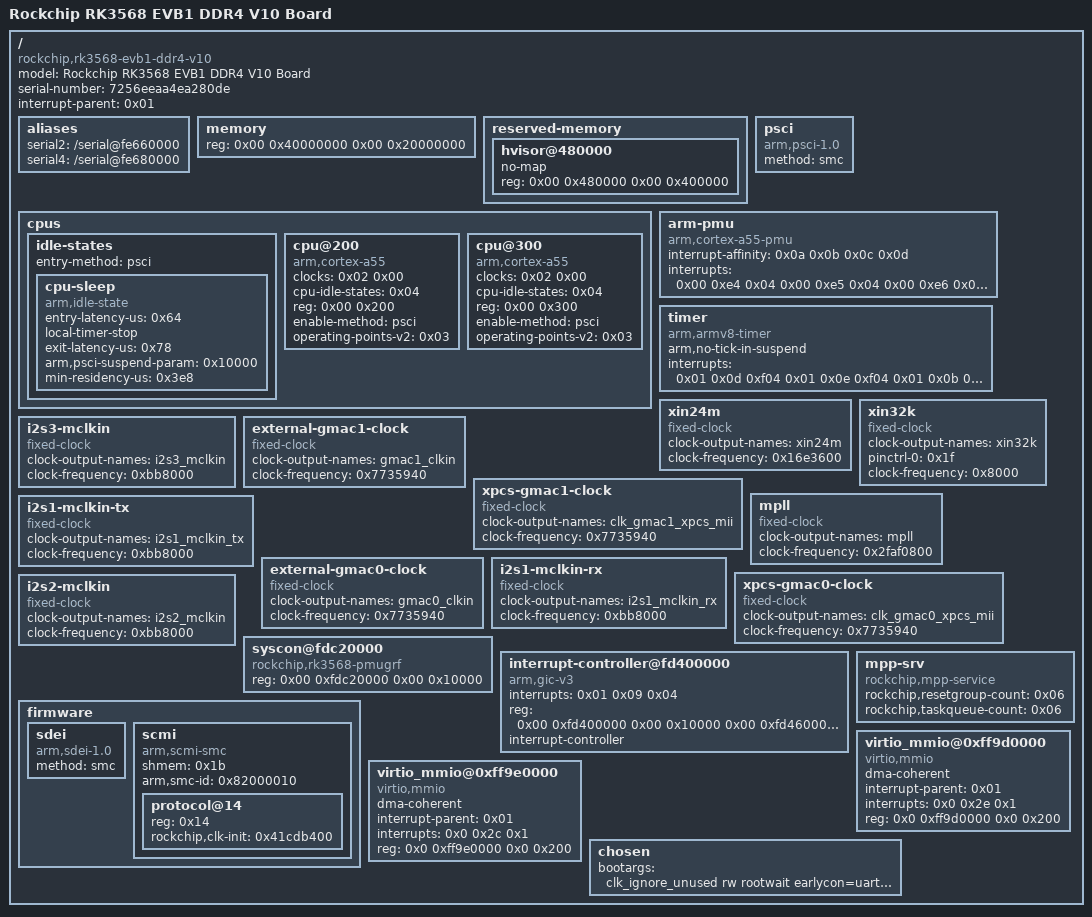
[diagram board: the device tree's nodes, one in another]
/dts-v1/;

/{
    #address-cells = <0x02>;
	model = "Rockchip RK3568 EVB1 DDR4 V10 Board";
	serial-number = "7256eeaa4ea280de";
	#size-cells = <0x02>;
	interrupt-parent = <0x01>;
	compatible = "rockchip,rk3568-evb1-ddr4-v10\0rockchip,rk3568";

	aliases {
		// mmc0 = "/sdhci@fe310000";
		serial2 = "/serial@fe660000";
		serial4 = "/serial@fe680000";
	};

    memory {
		device_type = "memory";
		reg = <0x00 0x40000000 0x00 0x20000000>;
	};
	
	reserved-memory {
		#address-cells = <0x02>;
		#size-cells = <0x02>;
		ranges;
		phandle = <0x142>;

        hvisor@480000 {
			no-map;
			reg = <0x00 0x480000 0x00 0x400000>;
		};
    };

	cpus {
		#address-cells = <0x02>;
		#size-cells = <0x00>;

		idle-states {
			entry-method = "psci";

			cpu-sleep {
				entry-latency-us = <0x64>;
				local-timer-stop;
				exit-latency-us = <0x78>;
				arm,psci-suspend-param = <0x10000>;
				compatible = "arm,idle-state";
				phandle = <0x04>;
				min-residency-us = <0x3e8>;
			};
		};

		// cpu@0 {
		// 	cpu-supply = <0x05>;
		// 	clocks = <0x02 0x00>;
		// 	cpu-idle-states = <0x04>;
		// 	device_type = "cpu";
		// 	compatible = "arm,cortex-a55";
		// 	dynamic-power-coefficient = <0xbb>;
		// 	reg = <0x00 0x00>;
		// 	enable-method = "psci";
		// 	phandle = <0x0a>;
		// 	// operating-points-v2 = <0x03>;
		// 	#cooling-cells = <0x02>;
		// };

		// cpu@100 {
		// 	clocks = <0x02 0x00>;
		// 	cpu-idle-states = <0x04>;
		// 	device_type = "cpu";
		// 	compatible = "arm,cortex-a55";
		// 	reg = <0x00 0x100>;
		// 	enable-method = "psci";
		// 	phandle = <0x0b>;
		// 	// operating-points-v2 = <0x03>;
		// };

		cpu@200 {
			clocks = <0x02 0x00>;
			cpu-idle-states = <0x04>;
			device_type = "cpu";
			compatible = "arm,cortex-a55";
			reg = <0x00 0x200>;
			enable-method = "psci";
			phandle = <0x0c>;
			operating-points-v2 = <0x03>;
		};

		cpu@300 {
			clocks = <0x02 0x00>;
			cpu-idle-states = <0x04>;
			device_type = "cpu";
			compatible = "arm,cortex-a55";
			reg = <0x00 0x300>;
			enable-method = "psci";
			phandle = <0x0d>;
			operating-points-v2 = <0x03>;
		};
	};

	psci {
		method = "smc";
		compatible = "arm,psci-1.0";
	};

    arm-pmu {
		interrupt-affinity = <0x0a 0x0b 0x0c 0x0d>;
		interrupts = <0x00 0xe4 0x04 0x00 0xe5 0x04 0x00 0xe6 0x04 0x00 0xe7 0x04>;
		compatible = "arm,cortex-a55-pmu\0arm,armv8-pmuv3";
	};

    timer {
		arm,no-tick-in-suspend;
		interrupts = <0x01 0x0d 0xf04 0x01 0x0e 0xf04 0x01 0x0b 0xf04 0x01 0x0a 0xf04>;
		compatible = "arm,armv8-timer";
	};

	// timer@fe5f0000 {
	// 	clock-names = "pclk\0timer";
	// 	interrupts = <0x00 0x6d 0x04>;
	// 	clocks = <0x20 0x16c 0x20 0x16d>;
	// 	compatible = "rockchip,rk3568-timer\0rockchip,rk3288-timer";
	// 	reg = <0x00 0xfe5f0000 0x00 0x1000>;
	// 	phandle = <0x1b6>;
	// };

	xin24m {
		clock-output-names = "xin24m";
		#clock-cells = <0x00>;
		clock-frequency = <0x16e3600>;
		compatible = "fixed-clock";
		phandle = <0x154>;
	};

    xin32k {
		pinctrl-names = "default";
		clock-output-names = "xin32k";
		pinctrl-0 = <0x1f>;
		#clock-cells = <0x00>;
		clock-frequency = <0x8000>;
		compatible = "fixed-clock";
		phandle = <0x155>;
	};

	i2s3-mclkin {
		clock-output-names = "i2s3_mclkin";
		#clock-cells = <0x00>;
		clock-frequency = <0xbb8000>;
		compatible = "fixed-clock";
		phandle = <0x152>;
	};

	external-gmac1-clock {
		clock-output-names = "gmac1_clkin";
		#clock-cells = <0x00>;
		clock-frequency = <0x7735940>;
		compatible = "fixed-clock";
		phandle = <0x14c>;
	};

	xpcs-gmac1-clock {
		clock-output-names = "clk_gmac1_xpcs_mii";
		#clock-cells = <0x00>;
		clock-frequency = <0x7735940>;
		compatible = "fixed-clock";
		phandle = <0x14e>;
	};

	mpll {
		clock-output-names = "mpll";
		#clock-cells = <0x00>;
		clock-frequency = <0x2faf0800>;
		compatible = "fixed-clock";
		phandle = <0x153>;
	};

	i2s1-mclkin-tx {
		clock-output-names = "i2s1_mclkin_tx";
		#clock-cells = <0x00>;
		clock-frequency = <0xbb8000>;
		compatible = "fixed-clock";
		phandle = <0x150>;
	};

	external-gmac0-clock {
		clock-output-names = "gmac0_clkin";
		#clock-cells = <0x00>;
		clock-frequency = <0x7735940>;
		compatible = "fixed-clock";
		phandle = <0x14b>;
	};

	i2s1-mclkin-rx {
		clock-output-names = "i2s1_mclkin_rx";
		#clock-cells = <0x00>;
		clock-frequency = <0xbb8000>;
		compatible = "fixed-clock";
		phandle = <0x14f>;
	};

	xpcs-gmac0-clock {
		clock-output-names = "clk_gmac0_xpcs_mii";
		#clock-cells = <0x00>;
		clock-frequency = <0x7735940>;
		compatible = "fixed-clock";
		phandle = <0x14d>;
	};

	i2s2-mclkin {
		clock-output-names = "i2s2_mclkin";
		#clock-cells = <0x00>;
		clock-frequency = <0xbb8000>;
		compatible = "fixed-clock";
		phandle = <0x151>;
	};

	syscon@fdc20000 {
		compatible = "rockchip,rk3568-pmugrf\0syscon\0simple-mfd";
		reg = <0x00 0xfdc20000 0x00 0x10000>;
		phandle = <0x35>;
	};

	// clock-controller@fdd00000 {
	// 	#reset-cells = <0x01>;
	// 	assigned-clocks = <0x33 0x32>;
	// 	assigned-clock-parents = <0x33 0x05>;
	// 	#clock-cells = <0x01>;
	// 	rockchip,pmugrf = <0x35>;
	// 	compatible = "rockchip,rk3568-pmucru";
	// 	rockchip,grf = <0x34>;
	// 	reg = <0x00 0xfdd00000 0x00 0x1000>;
	// 	phandle = <0x33>;
	// };

	// clock-controller@fdd20000 {
	// 	#reset-cells = <0x01>;
	// 	assigned-clocks = <0x33 0x05 0x20 0x106 0x20 0x10b 0x33 0x01 0x33 0x2b 0x20 0x03 0x20 0x19b 0x20 0x09 0x20 0x19c 0x20 0x19d 0x20 0x1a1 0x20 0x19e 0x20 0x19f 0x20 0x1a0 0x20 0x04 0x20 0x10d 0x20 0x10e 0x20 0x173 0x20 0x174 0x20 0x175 0x20 0x176 0x20 0xc9 0x20 0xca 0x20 0x06 0x20 0x7e 0x20 0x7f 0x20 0x3d 0x20 0x41 0x20 0x45 0x20 0x49 0x20 0x4d 0x20 0x4d 0x20 0x55 0x20 0x51 0x20 0x5d 0x20 0xdd>;
	// 	assigned-clock-parents = <0x33 0x08 0x20 0x04 0x20 0x04>;
	// 	assigned-clock-rates = <0x8000 0x11e1a300 0x11e1a300 0xbebc200 0x5f5e100 0x3b9aca00 0x1dcd6500 0x13d92d40 0xee6b280 0x7735940 0x5f5e100 0x3b9aca0 0x2faf080 0x17d7840 0x46cf7100 0x8f0d180 0x5f5e100 0x1dcd6500 0x17d78400 0x8f0d180 0x5f5e100 0x11e1a300 0x8f0d180 0x47868c00 0x17d78400 0x5f5e100 0x46cf7100 0x46cf7100 0x46cf7100 0x46cf7100 0x46cf7100 0x46cf7100 0x46cf7100 0x46cf7100 0x46cf7100 0x1dcd6500>;
	// 	#clock-cells = <0x01>;
	// 	compatible = "rockchip,rk3568-cru";
	// 	rockchip,grf = <0x34>;
	// 	reg = <0x00 0xfdd20000 0x00 0x1000>;
	// 	phandle = <0x20>;
	// };

	interrupt-controller@fd400000 {
		#address-cells = <0x02>;
		interrupts = <0x01 0x09 0x04>;
		#size-cells = <0x02>;
		compatible = "arm,gic-v3";
		ranges;
		#interrupt-cells = <0x03>;
		reg = <0x00 0xfd400000 0x00 0x10000 0x00 0xfd460000 0x00 0xc0000>;
		phandle = <0x01>;
		interrupt-controller;

		// interrupt-controller@fd440000 {
		// 	msi-controller;
		// 	compatible = "arm,gic-v3-its";
		// 	reg = <0x00 0xfd440000 0x00 0x20000>;
		// 	phandle = <0xad>;
		// 	#msi-cells = <0x01>;
		// };
	};

	// syscon@fdc60000 {
	// 	compatible = "rockchip,rk3568-grf\0syscon\0simple-mfd";
	// 	reg = <0x00 0xfdc60000 0x00 0x10000>;
	// 	phandle = <0x34>;
    // };

	// sdhci@fe310000 {
	// 	clock-names = "core\0bus\0axi\0block\0timer";
	// 	assigned-clocks = <0x20 0x7b 0x20 0x7d 0x20 0x7c>;
	// 	bus-width = <0x08>;
	// 	non-removable;
	// 	assigned-clock-rates = <0xbebc200 0x16e3600 0xbebc200>;
	// 	interrupts = <0x00 0x13 0x04>;
	// 	clocks = <0x20 0x7c 0x20 0x7a 0x20 0x79 0x20 0x7b 0x20 0x7d>;
	// 	compatible = "rockchip,dwcmshc-sdhci\0snps,dwcmshc-sdhci";
	// 	status = "okay";
	// 	reg = <0x00 0xfe310000 0x00 0x10000>;
	// 	phandle = <0x1a5>;
	// 	max-frequency = <0xbebc200>;
	// 	supports-emmc;
	// };

	// scmi-shmem@10f000 {
	// 	compatible = "arm,scmi-shmem";
	// 	reg = <0x00 0x10f000 0x00 0x100>;
	// 	phandle = <0x1b>;
	// };

	firmware {

		// optee {
		// 	method = "smc";
		// 	compatible = "linaro,optee-tz";
		// 	phandle = <0x13f>;
		// };

		sdei {
			method = "smc";
			compatible = "arm,sdei-1.0";
			phandle = <0x141>;
		};

		scmi { 
			shmem = <0x1b>;
			#address-cells = <0x01>;
			#size-cells = <0x00>;
			compatible = "arm,scmi-smc";
			phandle = <0x140>;
			arm,smc-id = <0x82000010>;

			protocol@14 {
				#clock-cells = <0x01>;
				reg = <0x14>;
				rockchip,clk-init = <0x41cdb400>;
				phandle = <0x02>;
			};
		};
	};

	mpp-srv {
		rockchip,resetgroup-count = <0x06>;
		rockchip,taskqueue-count = <0x06>;
		compatible = "rockchip,mpp-service";
		status = "okay";
		phandle = <0x6e>;
	};

	// dmac@fe530000 {
	// 	clock-names = "apb_pclk";
	// 	interrupts = <0x00 0x0e 0x04 0x00 0x0d 0x04>;
	// 	clocks = <0x20 0x10d>;
	// 	arm,pl330-periph-burst;
	// 	compatible = "arm,pl330\0arm,primecell";
	// 	reg = <0x00 0xfe530000 0x00 0x4000>;
	// 	phandle = <0x41>;
	// 	#dma-cells = <0x01>;
	// };

	// serial@fe660000 {
	// 	reg-io-width = <0x04>;
	// 	pinctrl-names = "default";
	// 	pinctrl-0 = <0xef>;
	// 	// clock-names = "baudclk\0apb_pclk";
	// 	interrupts = <0x00 0x76 0x04>;
	// 	// clocks = <0x20 0x123 0x20 0x120>;
	// 	compatible = "rockchip,rk3568-uart\0snps,dw-apb-uart";
	// 	status = "disabled";
	// 	reg = <0x00 0xfe660000 0x00 0x100>;
	// 	phandle = <0x1bd>;
	// 	// dmas = <0x41 0x04 0x41 0x05>;
	// 	reg-shift = <0x02>;
	// };

	// serial@fe680000 {
	// 	compatible = "rockchip,rk3568-uart\0snps,dw-apb-uart";
	// 	reg = <0x00 0xfe680000 0x00 0x100>;
	// 	interrupts = <0x00 0x78 0x04>;
	// 	// clocks = <0x1f 0x12b 0x1f 0x128>;
	// 	// clock-names = "baudclk\0apb_pclk";
	// 	reg-shift = <0x02>;
	// 	reg-io-width = <0x04>;
	// 	// dmas = <0x3f 0x08 0x3f 0x09>;
	// 	pinctrl-names = "default";
	// 	pinctrl-0 = <0xf0>;
	// 	status = "okay";
	// 	rockchip,baudrate = <0x1c200>;
	// 	phandle = <0x1b6>;
	// };

	// fiq-debugger {
	// 	pinctrl-names = "default";
	// 	rockchip,irq-mode-enable = <0x01>;
	// 	rockchip,baudrate = <0x16e360>;
	// 	pinctrl-0 = <0xef>;
	// 	interrupts = <0x00 0xfc 0x08>;
	// 	rockchip,wake-irq = <0x00>;
	// 	compatible = "rockchip,fiq-debugger";
	// 	status = "okay";
	// 	rockchip,serial-id = <0x02>;
	// };

	// virtio blk
	virtio_mmio@0xff9d0000 {
		dma-coherent;
		interrupt-parent = <0x01>;
		interrupts = <0x0 0x2e 0x1>;
		reg = <0x0 0xff9d0000 0x0 0x200>;
		compatible = "virtio,mmio";
		status = "okay";
	};
	
	// // virtio net
	// virtio_mmio@a003600 {
	// 	dma-coherent;
	// 	interrupt-parent = <0x01>;
	// 	interrupts = <0x0 0x2b 0x1>;
	// 	reg = <0x0 0xa003600 0x0 0x200>;
	// 	compatible = "virtio,mmio";
	// 	status = "disabled";
	// };

	// virtio serial
	virtio_mmio@0xff9e0000 {
		dma-coherent;
		interrupt-parent = <0x01>;
		interrupts = <0x0 0x2c 0x1>;
		reg = <0x0 0xff9e0000 0x0 0x200>;
		compatible = "virtio,mmio";
		status = "okay";
	};
	

	chosen {
		bootargs = "clk_ignore_unused rw rootwait earlycon=uart8250,mmio32,0xfe660000 console=hvc0 root=/dev/vda";
		// bootargs = "clk_ignore_unused rw rootwait earlycon=uart8250,mmio32,0xfe660000 console=ttyFIQ0 root=/dev/vda";
		// bootargs = "clk_ignore_unused earlycon=virtio,mmio,0xff9e0000 console=hvc0 root=/dev/vda rootwait rw";
		phandle = <0x1dd>;
	};
};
